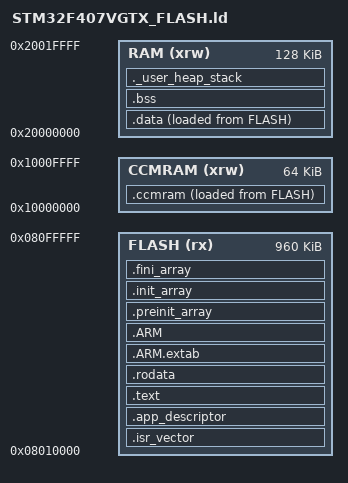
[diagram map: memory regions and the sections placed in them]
/*
******************************************************************************
**
** @file        : LinkerScript.ld
**
** @author      : Auto-generated by STM32CubeIDE
**
** @brief       : Linker script for STM32F407VGTx Device from STM32F4 series
**                      1024KBytes FLASH
**                      64KBytes CCMRAM
**                      128KBytes RAM
**
**                Set heap size, stack size and stack location according
**                to application requirements.
**
**                Set memory bank area and size if external memory is used
**
**  Target      : STMicroelectronics STM32
**
**  Distribution: The file is distributed as is, without any warranty
**                of any kind.
**
******************************************************************************
** @attention
**
** Copyright (c) 2026 STMicroelectronics.
** All rights reserved.
**
** This software is licensed under terms that can be found in the LICENSE file
** in the root directory of this software component.
** If no LICENSE file comes with this software, it is provided AS-IS.
**
******************************************************************************
*/

/* Entry Point */
ENTRY(Reset_Handler)

/* Highest address of the user mode stack */
_estack = ORIGIN(RAM) + LENGTH(RAM); /* end of "RAM" Ram type memory */

_Min_Heap_Size = 0x200; /* required amount of heap */
_Min_Stack_Size = 0x400; /* required amount of stack */

/* Memories definition
 *
 * Flash layout (STM32F407, 1 MB):
 *   0x08000000 – 0x0800FFFF  Bootloader (64 KB, sectors 0-3)
 *                             hwdef-bl.dat: FLASH_BOOTLOADER_LOAD_KB 64
 *   0x08010000               APP_START_ADDRESS – bootloader writes firmware HERE
 *                             and jumps to *(uint32_t*)0x08010000 as stack pointer,
 *                             *(uint32_t*)0x08010004 as Reset_Handler.
 *                             The .bin file MUST therefore start at 0x08010000
 *                             with the ISR vector table as its first bytes.
 *   0x08010000+              Application: ISR vector, app descriptor, code (960 KB)
 */
MEMORY
{
  CCMRAM   (xrw) : ORIGIN = 0x10000000, LENGTH = 64K
  RAM      (xrw) : ORIGIN = 0x20000000, LENGTH = 128K
  FLASH    (rx)  : ORIGIN = 0x08010000, LENGTH = 960K
}

/* Sections */
SECTIONS
{
  /* ISR vector at 0x08010000 – first bytes of .bin – bootloader reads SP+PC from here */
  .isr_vector :
  {
    . = ALIGN(4);
    KEEP(*(.isr_vector)) /* Startup code */
    . = ALIGN(4);
  } >FLASH

  /* App descriptor at exactly offset 0x200 from APP_START_ADDRESS.
   *
   * The official ArduPilot AP_Periph.bin for this board (sw-spar-f407) places
   * the descriptor at flash offset 0x200.  ChibiOS uses a 0x400-byte vector
   * table (256 entries); we use the standard STM32F407 98-entry table (0x188
   * bytes), so we pad to 0x200 to match the official layout exactly.
   *
   * The bootloader finds the descriptor anywhere via memmem(), so this is not
   * strictly required, but matching the reference layout eliminates any risk
   * of layout-dependent edge cases and makes the binary easier to inspect. */
  .app_descriptor :
  {
    . = ALIGN(0x200);      /* pad to 512-byte boundary -> descriptor at 0x08010200 */
    KEEP(*(.app_descriptor))
    . = ALIGN(4);
  } >FLASH

  /* The program code and other data into "FLASH" Rom type memory */
  .text :
  {
    . = ALIGN(4);
    *(.text)           /* .text sections (code) */
    *(.text*)          /* .text* sections (code) */
    *(.glue_7)         /* glue arm to thumb code */
    *(.glue_7t)        /* glue thumb to arm code */
    *(.eh_frame)

    KEEP (*(.init))
    KEEP (*(.fini))

    . = ALIGN(4);
    _etext = .;        /* define a global symbols at end of code */
  } >FLASH

  /* Constant data into "FLASH" Rom type memory */
  .rodata :
  {
    . = ALIGN(4);
    *(.rodata)         /* .rodata sections (constants, strings, etc.) */
    *(.rodata*)        /* .rodata* sections (constants, strings, etc.) */
    . = ALIGN(4);
  } >FLASH

  .ARM.extab (READONLY) : /* The "READONLY" keyword is only supported in GCC11 and later, remove it if using GCC10 or earlier. */
  {
    . = ALIGN(4);
    *(.ARM.extab* .gnu.linkonce.armextab.*)
    . = ALIGN(4);
  } >FLASH

  .ARM (READONLY) : /* The "READONLY" keyword is only supported in GCC11 and later, remove it if using GCC10 or earlier. */
  {
    . = ALIGN(4);
    __exidx_start = .;
    *(.ARM.exidx*)
    __exidx_end = .;
    . = ALIGN(4);
  } >FLASH

  .preinit_array (READONLY) : /* The "READONLY" keyword is only supported in GCC11 and later, remove it if using GCC10 or earlier. */
  {
    . = ALIGN(4);
    PROVIDE_HIDDEN (__preinit_array_start = .);
    KEEP (*(.preinit_array*))
    PROVIDE_HIDDEN (__preinit_array_end = .);
    . = ALIGN(4);
  } >FLASH

  .init_array (READONLY) : /* The "READONLY" keyword is only supported in GCC11 and later, remove it if using GCC10 or earlier. */
  {
    . = ALIGN(4);
    PROVIDE_HIDDEN (__init_array_start = .);
    KEEP (*(SORT(.init_array.*)))
    KEEP (*(.init_array*))
    PROVIDE_HIDDEN (__init_array_end = .);
    . = ALIGN(4);
  } >FLASH

  .fini_array (READONLY) : /* The "READONLY" keyword is only supported in GCC11 and later, remove it if using GCC10 or earlier. */
  {
    . = ALIGN(4);
    PROVIDE_HIDDEN (__fini_array_start = .);
    KEEP (*(SORT(.fini_array.*)))
    KEEP (*(.fini_array*))
    PROVIDE_HIDDEN (__fini_array_end = .);
    . = ALIGN(4);
  } >FLASH

  /* Used by the startup to initialize data */
  _sidata = LOADADDR(.data);

  /* Initialized data sections into "RAM" Ram type memory */
  .data :
  {
    . = ALIGN(4);
    _sdata = .;        /* create a global symbol at data start */
    *(.data)           /* .data sections */
    *(.data*)          /* .data* sections */
    *(.RamFunc)        /* .RamFunc sections */
    *(.RamFunc*)       /* .RamFunc* sections */

    . = ALIGN(4);
    _edata = .;        /* define a global symbol at data end */

  } >RAM AT> FLASH

  _siccmram = LOADADDR(.ccmram);

  /* CCM-RAM section
  *
  * IMPORTANT NOTE!
  * If initialized variables will be placed in this section,
  * the startup code needs to be modified to copy the init-values.
  */
  .ccmram :
  {
    . = ALIGN(4);
    _sccmram = .;       /* create a global symbol at ccmram start */
    *(.ccmram)
    *(.ccmram*)

    . = ALIGN(4);
    _eccmram = .;       /* create a global symbol at ccmram end */
  } >CCMRAM AT> FLASH

  /* Uninitialized data section into "RAM" Ram type memory */
  . = ALIGN(4);
  .bss :
  {
    /* This is used by the startup in order to initialize the .bss section */
    _sbss = .;         /* define a global symbol at bss start */
    __bss_start__ = _sbss;
    *(.bss)
    *(.bss*)
    *(COMMON)

    . = ALIGN(4);
    _ebss = .;         /* define a global symbol at bss end */
    __bss_end__ = _ebss;
  } >RAM

  /* User_heap_stack section, used to check that there is enough "RAM" Ram  type memory left */
  ._user_heap_stack :
  {
    . = ALIGN(8);
    PROVIDE ( end = . );
    PROVIDE ( _end = . );
    . = . + _Min_Heap_Size;
    . = . + _Min_Stack_Size;
    . = ALIGN(8);
  } >RAM

  /* Remove information from the compiler libraries */
  /DISCARD/ :
  {
    libc.a ( * )
    libm.a ( * )
    libgcc.a ( * )
  }

  .ARM.attributes 0 : { *(.ARM.attributes) }
}
